BO_ 0 BRIDGE_STATS: 48 XXX
 SG_ FRAMES_TOTAL : 7|16@0+ (1,0) [0|65535] "" XXX
 SG_ FRAMES_VALID : 23|16@0+ (1,0) [0|65535] "" XXX
 SG_ CRC_FAIL : 39|16@0+ (1,0) [0|65535] "" XXX
 SG_ JUNK : 55|16@0+ (1,0) [0|65535] "" XXX
 SG_ TAIL_INCOMPLETE : 71|16@0+ (1,0) [0|65535] "" XXX
 SG_ NOTIFY_DROPPED : 87|16@0+ (1,0) [0|65535] "" XXX
 SG_ INJECT_REQUESTS : 103|16@0+ (1,0) [0|65535] "" XXX
 SG_ INJECT_DONE : 119|16@0+ (1,0) [0|65535] "" XXX
 SG_ INJECT_MISSED : 135|16@0+ (1,0) [0|65535] "" XXX
 SG_ INJECT_REJECTED : 151|16@0+ (1,0) [0|65535] "" XXX
 SG_ INJECT_TABLE_FULL : 167|16@0+ (1,0) [0|65535] "" XXX
 SG_ CAN_TX : 183|16@0+ (1,0) [0|65535] "" XXX
 SG_ CAN_RX : 199|16@0+ (1,0) [0|65535] "" XXX
 SG_ CAN_OUT_DROPPED : 215|16@0+ (1,0) [0|65535] "" XXX
 SG_ DUP_DROPPED : 231|16@0+ (1,0) [0|65535] "" XXX
 SG_ RING_OVERRUN : 247|16@0+ (1,0) [0|65535] "" XXX
 SG_ CAN_INIT : 263|16@0+ (1,0) [0|65535] "" XXX

BO_ 368 RADAR_1: 20 XXX
 SG_ CYCLE_COUNT : 5|6@0+ (1,0) [0|63] "" XXX
 SG_ FLAGS : 7|2@0+ (1,0) [0|3] "" XXX
 SG_ LENGTH : 15|8@0+ (1,0) [0|255] "words" XXX
 SG_ INDEX : 23|8@0+ (1,0) [0|255] "" XXX
 SG_ A_0 : 24|8@1- (1,0) [-128|127] "" XXX
 SG_ B_0 : 32|8@1- (1,0) [-128|127] "" XXX
 SG_ A_1 : 40|8@1- (1,0) [-128|127] "" XXX
 SG_ B_1 : 48|8@1- (1,0) [-128|127] "" XXX
 SG_ A_2 : 56|8@1- (1,0) [-128|127] "" XXX
 SG_ B_2 : 64|8@1- (1,0) [-128|127] "" XXX
 SG_ A_3 : 72|8@1- (1,0) [-128|127] "" XXX
 SG_ B_3 : 80|8@1- (1,0) [-128|127] "" XXX
 SG_ A_4 : 88|8@1- (1,0) [-128|127] "" XXX
 SG_ B_4 : 96|8@1- (1,0) [-128|127] "" XXX
 SG_ A_5 : 104|8@1- (1,0) [-128|127] "" XXX
 SG_ B_5 : 112|8@1- (1,0) [-128|127] "" XXX
 SG_ A_6 : 120|8@1- (1,0) [-128|127] "" XXX
 SG_ B_6 : 128|8@1- (1,0) [-128|127] "" XXX
 SG_ COUNTER : 136|8@1+ (1,0) [0|255] "" XXX

BO_ 384 RADAR_2: 20 XXX
 SG_ CYCLE_COUNT : 5|6@0+ (1,0) [0|63] "" XXX
 SG_ FLAGS : 7|2@0+ (1,0) [0|3] "" XXX
 SG_ LENGTH : 15|8@0+ (1,0) [0|255] "words" XXX
 SG_ INDEX : 23|8@0+ (1,0) [0|255] "" XXX
 SG_ A_0 : 24|8@1- (1,0) [-128|127] "" XXX
 SG_ B_0 : 32|8@1- (1,0) [-128|127] "" XXX
 SG_ A_1 : 40|8@1- (1,0) [-128|127] "" XXX
 SG_ B_1 : 48|8@1- (1,0) [-128|127] "" XXX
 SG_ A_2 : 56|8@1- (1,0) [-128|127] "" XXX
 SG_ B_2 : 64|8@1- (1,0) [-128|127] "" XXX
 SG_ A_3 : 72|8@1- (1,0) [-128|127] "" XXX
 SG_ B_3 : 80|8@1- (1,0) [-128|127] "" XXX
 SG_ A_4 : 88|8@1- (1,0) [-128|127] "" XXX
 SG_ B_4 : 96|8@1- (1,0) [-128|127] "" XXX
 SG_ A_5 : 104|8@1- (1,0) [-128|127] "" XXX
 SG_ B_5 : 112|8@1- (1,0) [-128|127] "" XXX
 SG_ A_6 : 120|8@1- (1,0) [-128|127] "" XXX
 SG_ B_6 : 128|8@1- (1,0) [-128|127] "" XXX
 SG_ COUNTER : 136|8@1+ (1,0) [0|255] "" XXX

BO_ 400 WHEEL_ODOMETRY: 20 XXX
 SG_ CYCLE_COUNT : 5|6@0+ (1,0) [0|63] "" XXX
 SG_ DIRECTION : 7|2@0+ (1,0) [0|3] "" XXX
 SG_ LENGTH : 15|8@0+ (1,0) [0|255] "words" XXX
 SG_ CHECKSUM : 23|8@0+ (1,0) [0|255] "" XXX
 SG_ COUNTER : 27|4@0+ (1,0) [0|15] "" XXX
 SG_ WHEEL_1 : 32|16@1+ (1,0) [0|65535] "" XXX
 SG_ WHEEL_2 : 56|16@1+ (1,0) [0|65535] "" XXX
 SG_ WHEEL_3 : 72|16@1+ (1,0) [0|65535] "" XXX
 SG_ WHEEL_4 : 96|16@1+ (1,0) [0|65535] "" XXX
 SG_ COUNTER_SOMETHING : 112|16@1+ (1,0) [0|65535] "" XXX

BO_ 432 BRAKES: 20 XXX
 SG_ CYCLE_COUNT : 5|6@0+ (1,0) [0|63] "" XXX
 SG_ DIRECTION : 7|2@0+ (1,0) [0|3] "" XXX
 SG_ LENGTH : 15|8@0+ (1,0) [0|255] "words" XXX
 SG_ CHECKSUM : 23|8@0+ (1,0) [0|255] "" XXX
 SG_ COUNTER : 27|4@0+ (1,0) [0|15] "" XXX
 SG_ BRAKE_PRESSURE_1 : 32|16@1+ (1,0) [0|65535] "" XXX
 SG_ BRAKE_PRESSURE_2 : 48|16@1+ (1,0) [0|65535] "" XXX
 SG_ BRAKE_PRESSURE_3 : 64|16@1+ (1,0) [0|65535] "" XXX
 SG_ BRAKE_PRESSURE_4 : 80|16@1+ (1,0) [0|65535] "" XXX
 SG_ NEW_SIGNAL_1 : 99|1@0+ (1,0) [0|1] "" XXX
 SG_ NEW_SIGNAL_2 : 103|2@0+ (1,0) [0|3] "" XXX
 SG_ NEW_SIGNAL_5 : 105|2@0+ (1,0) [0|3] "" XXX
 SG_ NEW_SIGNAL_7 : 115|1@0+ (1,0) [0|1] "" XXX
 SG_ NEW_SIGNAL_3 : 119|2@0+ (1,0) [0|3] "" XXX
 SG_ NEW_SIGNAL_8 : 123|1@0+ (1,0) [0|1] "" XXX
 SG_ NEW_SIGNAL_4 : 127|2@0+ (1,0) [0|3] "" XXX
 SG_ NEW_SIGNAL_6 : 135|8@0+ (1,0) [0|255] "" XXX

BO_ 512 NEW_MSG_2000: 20 XXX
 SG_ CYCLE_COUNT : 5|6@0+ (1,0) [0|63] "" XXX
 SG_ DIRECTION : 7|2@0+ (1,0) [0|3] "" XXX
 SG_ LENGTH : 15|8@0+ (1,0) [0|255] "words" XXX
 SG_ NEW_SIGNAL_1 : 28|12@1+ (1,0) [0|8191] "" XXX
 SG_ NEW_SIGNAL_2 : 40|12@1+ (1,0) [0|4095] "" XXX
 SG_ NEW_SIGNAL_3 : 52|12@1+ (1,0) [0|8191] "" XXX

BO_ 608 NEW_MSG_2600: 20 XXX
 SG_ CYCLE_COUNT : 5|6@0+ (1,0) [0|63] "" XXX
 SG_ DIRECTION : 7|2@0+ (1,0) [0|3] "" XXX
 SG_ LENGTH : 15|8@0+ (1,0) [0|255] "words" XXX
 SG_ NEW_SIGNAL_1 : 40|16@1+ (1,0) [0|2047] "" XXX

BO_ 624 STEERING_WHEEL_7: 20 XXX
 SG_ MULTIPLEXOR M : 16|1@0+ (1,0) [0|1] "" XXX
 SG_ NEW_SIGNAL_1 m0 : 111|8@0+ (1,0) [0|255] "" XXX
 SG_ NEW_SIGNAL_2 m0 : 119|8@0+ (1,0) [0|255] "" XXX
 SG_ CYCLE_COUNT : 5|6@0+ (1,0) [0|63] "" XXX
 SG_ DIRECTION : 7|2@0+ (1,0) [0|3] "" XXX
 SG_ LENGTH : 15|8@0+ (1,0) [0|255] "words" XXX

BO_ 625 STEERING_WHEEL_4: 20 XXX
 SG_ CYCLE_COUNT : 5|6@0+ (1,0) [0|63] "" XXX
 SG_ DIRECTION : 7|2@0+ (1,0) [0|3] "" XXX
 SG_ LENGTH : 15|8@0+ (1,0) [0|255] "words" XXX
 SG_ CHECKSUM : 23|8@0+ (1,0) [0|255] "" XXX
 SG_ COUNTER : 27|4@0+ (1,0) [0|15] "" XXX
 SG_ STEERING_ANGLE : 32|16@1+ (0.04395,-1440.1536) [0|3] "" XXX
 SG_ COUNTER_SOMETHING : 80|12@1+ (1,0) [0|4095] "" XXX

BO_ 641 GEARBOX_1: 20 XXX
 SG_ CYCLE_COUNT : 5|6@0+ (1,0) [0|63] "" XXX
 SG_ DIRECTION : 7|2@0+ (1,0) [0|3] "" XXX
 SG_ LENGTH : 15|8@0+ (1,0) [0|255] "words" XXX
 SG_ CHECKSUM : 23|8@0+ (1,0) [0|255] "" XXX
 SG_ COUNTER : 27|4@0+ (1,0) [0|15] "" XXX
 SG_ RPM : 58|14@1+ (1,0) [0|65535] "" XXX
 SG_ COUNTER_SOMETHING : 80|12@1+ (1,0) [0|65535] "" XXX
 SG_ TORQUE_REQUEST_MAYBE : 112|12@1+ (1,0) [0|65535] "" XXX

BO_ 643 GEARBOX_2: 20 XXX
 SG_ CYCLE_COUNT : 5|6@0+ (1,0) [0|63] "" XXX
 SG_ DIRECTION : 7|2@0+ (1,0) [0|3] "" XXX
 SG_ LENGTH : 15|8@0+ (1,0) [0|255] "words" XXX
 SG_ CHECKSUM : 23|8@0+ (1,0) [0|255] "" XXX
 SG_ COUNTER : 27|4@0+ (1,0) [0|15] "" XXX
 SG_ GEAR : 35|4@0+ (1,0) [0|7] "" XXX
 SG_ OUTPUT_SPEED : 40|16@1+ (1,-2000) [0|255] "" XXX
 SG_ PARK_LOCKED : 57|1@0+ (1,0) [0|1] "" XXX

BO_ 657 NEW_MSG_2901: 20 XXX
 SG_ CYCLE_COUNT : 5|6@0+ (1,0) [0|63] "" XXX
 SG_ DIRECTION : 7|2@0+ (1,0) [0|3] "" XXX
 SG_ LENGTH : 15|8@0+ (1,0) [0|255] "words" XXX
 SG_ CHECKSUM : 23|8@0+ (1,0) [0|255] "" XXX
 SG_ COUNTER : 27|4@0+ (1,0) [0|15] "" XXX
 SG_ NEW_SIGNAL_4 : 32|16@1+ (1,-32768) [0|65535] "" XXX
 SG_ NEW_SIGNAL_3 : 48|16@1+ (1,-32768) [0|65535] "" XXX
 SG_ NEW_SIGNAL_1 : 104|16@1+ (1,-32768) [0|65535] "" XXX
 SG_ NEW_SIGNAL_2 : 128|16@1+ (1,-32768) [0|65535] "" XXX

BO_ 672 NEW_MSG_2A00: 20 XXX
 SG_ CYCLE_COUNT : 5|6@0+ (1,0) [0|63] "" XXX
 SG_ DIRECTION : 7|2@0+ (1,0) [0|3] "" XXX
 SG_ LENGTH : 15|8@0+ (1,0) [0|255] "words" XXX

BO_ 689 BRAKE_PEDAL_1: 20 XXX
 SG_ CYCLE_COUNT : 5|6@0+ (1,0) [0|63] "" XXX
 SG_ DIRECTION : 7|2@0+ (1,0) [0|3] "" XXX
 SG_ LENGTH : 15|8@0+ (1,0) [0|255] "words" XXX
 SG_ CHECKSUM : 23|8@0+ (1,0) [0|255] "" XXX
 SG_ COUNTER : 27|4@0+ (1,0) [0|15] "" XXX
 SG_ BRAKE_RELEASED_1 : 44|1@0+ (1,0) [0|1] "" XXX
 SG_ BRAKE_RELEASED_2 : 46|1@0+ (1,0) [0|1] "" XXX
 SG_ BRAKE_RELEASED_3 : 47|1@0+ (1,0) [0|1] "" XXX
 SG_ EPB_ENGAGE_SOMETHING : 49|2@0+ (1,0) [0|3] "" XXX
 SG_ EPB_RELEASE_SOMETHING : 51|2@0+ (1,0) [0|3] "" XXX
 SG_ NEW_SIGNAL_1 : 53|2@0+ (1,0) [0|3] "" XXX
 SG_ BRAKE_PRESSURE_SOMETHING : 87|8@0+ (1,0) [0|255] "" XXX
 SG_ BRAKE_PEDAL_POSITION_INV : 96|16@1+ (1,0) [0|65535] "" XXX
 SG_ BRAKE_PEDAL_POSITION_1 : 112|12@1+ (1,0) [0|4095] "" XXX
 SG_ BRAKE_PEDAL_POSITION_2 : 124|12@1+ (1,0) [0|15] "" XXX

BO_ 691 BRAKE_PEDAL_2: 20 XXX
 SG_ CYCLE_COUNT : 5|6@0+ (1,0) [0|63] "" XXX
 SG_ DIRECTION : 7|2@0+ (1,0) [0|3] "" XXX
 SG_ LENGTH : 15|8@0+ (1,0) [0|255] "words" XXX
 SG_ CHECKSUM : 23|8@0+ (1,0) [0|255] "" XXX
 SG_ COUNTER : 27|4@0+ (1,0) [0|15] "" XXX
 SG_ BRAKE_PEDAL_POSITION_INV_1 : 32|16@1+ (1,0) [0|65535] "" XXX
 SG_ BRAKE_PEDAL_POSITION_INV_2 : 56|16@1+ (1,0) [0|65535] "" XXX
 SG_ BRAKE_PEDAL_POSITION_3 : 79|8@0+ (1,0) [0|255] "" XXX

BO_ 736 WHEEL_SPEEDS: 20 XXX
 SG_ CYCLE_COUNT : 5|6@0+ (1,0) [0|63] "" XXX
 SG_ DIRECTION : 7|2@0+ (1,0) [0|3] "" XXX
 SG_ LENGTH : 15|8@0+ (1,0) [0|255] "words" XXX
 SG_ CHECKSUM : 23|8@0+ (1,0) [0|255] "" XXX
 SG_ COUNTER : 27|4@0+ (1,0) [0|15] "" XXX
 SG_ RL : 32|16@1+ (0.0198863636363636,-652) [0|65535] "km/h" XXX
 SG_ RR : 48|16@1+ (0.0198863636363636,-652) [0|65535] "km/h" XXX
 SG_ FL : 64|16@1+ (0.0198863636363636,-652) [0|65535] "km/h" XXX
 SG_ FR : 80|16@1+ (0.0198863636363636,-652) [0|65535] "km/h" XXX
 SG_ RR_STATE : 99|4@0+ (1,0) [0|15] "" XXX
 SG_ FL_STATE : 103|4@0+ (1,0) [0|15] "" XXX
 SG_ FR_STATE : 107|4@0+ (1,0) [0|15] "" XXX
 SG_ RL_STATE : 111|4@0+ (1,0) [0|15] "" XXX

BO_ 753 BRAKE_PEDAL_3: 20 XXX
 SG_ CYCLE_COUNT : 5|6@0+ (1,0) [0|63] "" XXX
 SG_ DIRECTION : 7|2@0+ (1,0) [0|3] "" XXX
 SG_ LENGTH : 15|8@0+ (1,0) [0|255] "words" XXX
 SG_ CHECKSUM : 23|8@0+ (1,0) [0|255] "" XXX
 SG_ COUNTER : 27|4@0+ (1,0) [0|15] "" XXX
 SG_ BRAKE_PRESSED_3 : 74|3@0+ (1,0) [0|7] "" XXX
 SG_ NEW_SIGNAL_1 : 75|1@0+ (1,0) [0|1] "" XXX
 SG_ STANDSTILL_SOMETHING : 76|1@0+ (1,0) [0|1] "" XXX
 SG_ NEW_SIGNAL_2 : 79|1@0+ (1,0) [0|1] "" XXX
 SG_ COUNTER_2 : 91|4@0+ (1,0) [0|15] "" XXX
 SG_ BRAKE_PRESSED_2 : 120|1@0+ (1,0) [0|1] "" XXX
 SG_ BRAKE_PRESSED_1 : 122|1@0+ (1,0) [0|1] "" XXX
 SG_ BRAKE_PRESSED_4 : 141|1@0+ (1,0) [0|1] "" XXX

BO_ 784 STEERING_WHEEL_5: 20 XXX
 SG_ CYCLE_COUNT : 5|6@0+ (1,0) [0|63] "" XXX
 SG_ DIRECTION : 7|2@0+ (1,0) [0|3] "" XXX
 SG_ LENGTH : 15|8@0+ (1,0) [0|255] "words" XXX
 SG_ CHECKSUM : 23|8@0+ (1,0) [0|255] "" XXX
 SG_ COUNTER : 27|4@0+ (1,0) [0|15] "" XXX
 SG_ STEERING_TORQUE_1 : 32|12@1+ (0.005,-10) [0|255] "Nm" XXX
 SG_ NEW_SIGNAL_2 : 80|12@1+ (1,0) [0|65535] "" XXX
 SG_ STEERING_TORQUE_2 : 96|12@1+ (0.005,-10) [0|4095] "Nm" XXX
 SG_ NEW_SIGNAL_1 : 115|4@0+ (1,0) [0|15] "" XXX

BO_ 785 STEERING_WHEEL_6: 20 XXX
 SG_ CYCLE_COUNT : 5|6@0+ (1,0) [0|63] "" XXX
 SG_ DIRECTION : 7|2@0+ (1,0) [0|3] "" XXX
 SG_ LENGTH : 15|8@0+ (1,0) [0|255] "words" XXX
 SG_ CHECKSUM : 23|8@0+ (1,0) [0|255] "" XXX
 SG_ COUNTER : 27|4@0+ (1,0) [0|15] "" XXX
 SG_ STEERING_RATE_SOMETHING : 71|8@0+ (1,0) [0|255] "" XXX

BO_ 816 STEERING_WHEEL_3: 20 XXX
 SG_ CYCLE_COUNT : 5|6@0+ (1,0) [0|63] "" XXX
 SG_ DIRECTION : 7|2@0+ (1,0) [0|3] "" XXX
 SG_ LENGTH : 15|8@0+ (1,0) [0|255] "words" XXX
 SG_ CHECKSUM : 23|8@0+ (1,0) [0|255] "" XXX
 SG_ COUNTER : 27|4@0+ (1,0) [0|15] "" XXX
 SG_ STEERING_ANGLE : 32|16@1+ (0.04395,-1440.1536) [0|65535] "" XXX
 SG_ NEW_SIGNAL_2 : 55|8@0+ (1,0) [0|255] "" XXX
 SG_ NEW_SIGNAL_1 : 63|8@0+ (1,0) [0|255] "" XXX
 SG_ NEW_SIGNAL_3 : 77|2@0+ (1,0) [0|3] "" XXX
 SG_ STEERING_TORQUE_EPS : 96|12@1+ (1,-1000) [0|4095] "" XXX

BO_ 880 SPEED: 20 XXX
 SG_ CYCLE_COUNT : 5|6@0+ (1,0) [0|63] "" XXX
 SG_ DIRECTION : 7|2@0+ (1,0) [0|3] "" XXX
 SG_ LENGTH : 15|8@0+ (1,0) [0|255] "words" XXX
 SG_ VEHICLE_SPEED : 32|16@1+ (0.015625,0) [0|65535] "" XXX
 SG_ DRIVING_STATUS : 52|2@1+ (1,0) [0|7] "" XXX

BO_ 897 KINEMATICS_1: 20 XXX
 SG_ CYCLE_COUNT : 5|6@0+ (1,0) [0|63] "" XXX
 SG_ DIRECTION : 7|2@0+ (1,0) [0|3] "" XXX
 SG_ LENGTH : 15|8@0+ (1,0) [0|255] "words" XXX
 SG_ CHECKSUM : 23|8@0+ (1,0) [0|255] "" XXX
 SG_ COUNTER : 27|4@0+ (1,0) [0|15] "" XXX
 SG_ PITCH : 32|12@1+ (1,0) [0|65535] "" XXX
 SG_ ROLL : 48|12@1+ (1,0) [0|65535] "" XXX
 SG_ Z_RATE_MAYBE : 64|12@1+ (1,0) [0|65535] "" XXX
 SG_ COUNTER_SOMETHING : 80|12@1+ (1,0) [0|65535] "" XXX
 SG_ YAW_RATE : 96|16@1+ (1,-32768) [0|65535] "" XXX

BO_ 898 KINEMATICS_2: 20 XXX
 SG_ CYCLE_COUNT : 5|6@0+ (1,0) [0|63] "" XXX
 SG_ DIRECTION : 7|2@0+ (1,0) [0|3] "" XXX
 SG_ LENGTH : 15|8@0+ (1,0) [0|255] "words" XXX
 SG_ CHECKSUM : 87|8@0+ (1,0) [0|255] "" XXX
 SG_ COUNTER : 91|4@0+ (1,0) [0|15] "" XXX
 SG_ YAW_RATE : 96|16@1+ (1,-32768) [0|65535] "" XXX

BO_ 913 KINEMATICS_3: 20 XXX
 SG_ CYCLE_COUNT : 5|6@0+ (1,0) [0|63] "" XXX
 SG_ DIRECTION : 7|2@0+ (1,0) [0|3] "" XXX
 SG_ LENGTH : 15|8@0+ (1,0) [0|255] "words" XXX
 SG_ CHECKSUM : 23|8@0+ (1,0) [0|255] "" XXX
 SG_ COUNTER : 27|4@0+ (1,0) [0|15] "" XXX
 SG_ YAW_RATE : 32|16@1+ (1,-32768) [0|65535] "" XXX

BO_ 914 KINEMATICS_4: 20 XXX
 SG_ CYCLE_COUNT : 5|6@0+ (1,0) [0|63] "" XXX
 SG_ DIRECTION : 7|2@0+ (1,0) [0|3] "" XXX
 SG_ LENGTH : 15|8@0+ (1,0) [0|255] "words" XXX
 SG_ CHECKSUM : 23|8@0+ (1,0) [0|255] "" XXX
 SG_ COUNTER : 27|4@0+ (1,0) [0|15] "" XXX
 SG_ ACCELERATION : 32|16@1+ (0.0025,-81.25) [0|65535] "" XXX
 SG_ SPEED : 48|16@1+ (1,0) [0|65535] "" XXX

BO_ 915 KINEMATICS_5: 20 XXX
 SG_ CYCLE_COUNT : 5|6@0+ (1,0) [0|63] "" XXX
 SG_ DIRECTION : 7|2@0+ (1,0) [0|3] "" XXX
 SG_ LENGTH : 15|8@0+ (1,0) [0|255] "words" XXX
 SG_ CHECKSUM : 23|8@0+ (1,0) [0|255] "" XXX
 SG_ COUNTER : 27|4@0+ (1,0) [0|15] "" XXX
 SG_ YAW_RATE : 32|16@1+ (1,-32768) [0|65535] "" XXX

BO_ 929 NEW_MSG_3A01: 20 XXX
 SG_ VALID M : 30|1@0+ (1,0) [0|1] "" XXX
 SG_ COUNTER m1 : 27|4@0+ (1,0) [0|15] "" XXX
 SG_ CYCLE_COUNT : 5|6@0+ (1,0) [0|63] "" XXX
 SG_ DIRECTION : 7|2@0+ (1,0) [0|3] "" XXX
 SG_ LENGTH : 15|8@0+ (1,0) [0|255] "words" XXX
 SG_ CHECKSUM : 23|8@0+ (1,0) [0|255] "" XXX

BO_ 930 NEW_MSG_3A02: 20 XXX
 SG_ CYCLE_COUNT : 5|6@0+ (1,0) [0|63] "" XXX
 SG_ DIRECTION : 7|2@0+ (1,0) [0|3] "" XXX
 SG_ LENGTH : 15|8@0+ (1,0) [0|255] "words" XXX
 SG_ CHECKSUM : 23|8@0+ (1,0) [0|255] "" XXX
 SG_ COUNTER : 27|4@0+ (1,0) [0|15] "" XXX

BO_ 931 CRUISE_STATE: 20 XXX
 SG_ CYCLE_COUNT : 5|6@0+ (1,0) [0|63] "" XXX
 SG_ DIRECTION : 7|2@0+ (1,0) [0|3] "" XXX
 SG_ LENGTH : 15|8@0+ (1,0) [0|255] "words" XXX
 SG_ CHECKSUM : 23|8@0+ (1,0) [0|255] "" XXX
 SG_ COUNTER : 27|4@0+ (1,0) [0|15] "" XXX
 SG_ SET_ME_0x2 : 31|4@0+ (1,0) [0|15] "" XXX
 SG_ SET_ME_0xFA : 47|8@0+ (1,0) [0|255] "" XXX
 SG_ ACCELERATION_REQUEST : 48|16@1+ (0.0015,-48) [-48|50.3] "m/s2" XXX
 SG_ CRUISE_ENGAGED_1 : 67|1@0+ (1,0) [0|1] "" XXX
 SG_ CRUISE_ENGAGED_2 : 69|1@0+ (1,0) [0|1] "" XXX
 SG_ SET_ME_0x1 : 73|1@0+ (1,0) [0|1] "" XXX
 SG_ CRUISE_ENGAGED_3 : 75|2@0+ (1,0) [0|3] "" XXX
 SG_ SET_ME_0xFFFF : 80|16@1+ (1,0) [0|65535] "" XXX
 SG_ NEW_SIGNAL_2 : 96|11@1+ (1,0) [0|2047] "" XXX
 SG_ SET_ME_0xF : 107|5@1+ (1,0) [0|31] "" XXX
 SG_ SET_ME_0xFFFFFFFF : 112|32@1+ (1,0) [0|4294967295] "" XXX

BO_ 944 STEERING_WHEEL_1: 20 XXX
 SG_ CYCLE_COUNT : 5|6@0+ (1,0) [0|63] "" XXX
 SG_ DIRECTION : 7|2@0+ (1,0) [0|3] "" XXX
 SG_ LENGTH : 15|8@0+ (1,0) [0|255] "words" XXX
 SG_ CHECKSUM : 23|8@0+ (1,0) [0|255] "" XXX
 SG_ COUNTER : 27|4@0+ (1,0) [0|15] "" XXX
 SG_ STEERING_ANGLE : 32|16@1+ (0.04395,-1440.1536) [0|65535] "" XXX

BO_ 945 STEERING_WHEEL_2: 20 XXX
 SG_ CYCLE_COUNT : 5|6@0+ (1,0) [0|63] "" XXX
 SG_ DIRECTION : 7|2@0+ (1,0) [0|3] "" XXX
 SG_ LENGTH : 15|8@0+ (1,0) [0|255] "words" XXX
 SG_ STEERING_ANGLE_1 : 24|16@1+ (0.04395,-1098.75) [0|65535] "" XXX
 SG_ STEER_TORQUE_SOMETHING : 40|12@1+ (1,-2046) [0|65535] "" XXX
 SG_ NEW_SIGNAL_2 : 62|1@0+ (1,0) [0|1] "" XXX
 SG_ HANDS_OFF_WHEEL : 63|1@0+ (1,0) [0|1] "" XXX
 SG_ STEERING_ANGLE_2 : 96|16@1+ (0.04395,-1098.75) [0|65535] "" XXX
 SG_ NEW_SIGNAL_1 : 113|2@0+ (1,0) [0|3] "" XXX

BO_ 1088 EPS_CONTROL: 20 XXX
 SG_ CYCLE_COUNT : 5|6@0+ (1,0) [0|63] "" XXX
 SG_ DIRECTION : 7|2@0+ (1,0) [0|3] "" XXX
 SG_ LENGTH : 15|8@0+ (1,0) [0|255] "words" XXX
 SG_ CHECKSUM_1 : 23|8@0+ (1,0) [0|255] "" XXX
 SG_ COUNTER_1 : 27|4@0+ (1,0) [0|15] "" XXX
 SG_ SET_ME_0xF_1 : 31|4@0+ (1,0) [0|15] "" XXX
 SG_ SET_ME_0xD0 : 39|8@0+ (1,0) [0|255] "" XXX
 SG_ SET_ME_0xE7 : 47|8@0+ (1,0) [0|255] "" XXX
 SG_ NEW_SIGNAL_2 : 55|8@0+ (1,0) [0|255] "" XXX
 SG_ NEW_SIGNAL_1 : 56|8@1+ (1,0) [0|255] "" XXX
 SG_ NEW_SIGNAL_7 : 67|4@0+ (1,0) [0|7] "" XXX
 SG_ TORQUE_MODE : 75|4@0+ (1,0) [0|15] "" XXX
 SG_ TORQUE_REQUEST_1 : 76|1@0+ (1,0) [0|1] "" XXX
 SG_ CHECKSUM_2 : 87|8@0+ (1,0) [0|255] "" XXX
 SG_ COUNTER_2 : 91|4@0+ (1,0) [0|15] "" XXX
 SG_ SET_ME_0xF_2 : 95|4@0+ (1,0) [0|15] "" XXX
 SG_ TORQUE : 96|12@1+ (0.005,-10) [0|4095] "Nm" XXX
 SG_ TORQUE_MODE_CPY : 111|4@0+ (1,0) [0|15] "" XXX
 SG_ SET_ME_0xFF_1 : 119|8@0+ (1,0) [0|255] "" XXX
 SG_ SET_ME_0xFF_2 : 127|8@0+ (1,0) [0|255] "" XXX
 SG_ SET_ME_0xF_3 : 131|4@0+ (1,0) [0|15] "" XXX
 SG_ TORQUE_REQUEST_2 : 133|2@0+ (1,0) [0|3] "" XXX
 SG_ LKA_STATE : 139|4@0+ (1,0) [0|255] "" XXX
 SG_ TORQUE_REQUEST_3 : 140|1@0+ (1,0) [0|1] "" XXX

BO_ 1089 NEW_MSG_4401: 20 XXX
 SG_ CYCLE_COUNT : 5|6@0+ (1,0) [0|63] "" XXX
 SG_ DIRECTION : 7|2@0+ (1,0) [0|3] "" XXX
 SG_ LENGTH : 15|8@0+ (1,0) [0|255] "words" XXX
 SG_ NEW_SIGNAL_1 : 71|4@0+ (1,0) [0|15] "" XXX
 SG_ NEW_SIGNAL_2 : 79|8@0+ (1,0) [0|255] "" XXX

BO_ 1090 NEW_MSG_4402: 20 XXX
 SG_ CYCLE_COUNT : 5|6@0+ (1,0) [0|63] "" XXX
 SG_ DIRECTION : 7|2@0+ (1,0) [0|3] "" XXX
 SG_ LENGTH : 15|8@0+ (1,0) [0|255] "words" XXX
 SG_ NEW_SIGNAL_1 : 143|8@0+ (1,0) [0|255] "" XXX

BO_ 1104 STEERING_WHEEL_8: 20 XXX
 SG_ CYCLE_COUNT : 5|6@0+ (1,0) [0|63] "" XXX
 SG_ DIRECTION : 7|2@0+ (1,0) [0|3] "" XXX
 SG_ LENGTH : 15|8@0+ (1,0) [0|255] "words" XXX
 SG_ CHECKSUM : 23|8@0+ (1,0) [0|255] "" XXX
 SG_ COUNTER : 27|4@0+ (1,0) [0|15] "" XXX
 SG_ STEERING_ANGLE_1 : 32|16@1+ (1,-32768) [0|65535] "" XXX
 SG_ STEERING_ANGLE_2 : 64|16@1+ (1,-32768) [0|65535] "" XXX
 SG_ STEERING_ANGLE_3 : 80|16@1+ (1,-32768) [0|511] "" XXX

BO_ 1123 NEW_MSG_4603: 20 XXX
 SG_ CYCLE_COUNT : 5|6@0+ (1,0) [0|63] "" XXX
 SG_ DIRECTION : 7|2@0+ (1,0) [0|3] "" XXX
 SG_ LENGTH : 15|8@0+ (1,0) [0|255] "words" XXX
 SG_ CHECKSUM : 23|8@0+ (1,0) [0|255] "" XXX
 SG_ COUNTER : 27|4@0+ (1,0) [0|15] "" XXX
 SG_ CRUISE_STATE_RELATED : 39|8@0+ (1,0) [0|255] "" XXX

BO_ 1152 CRUISE_STATE_2: 20 SAS
 SG_ CYCLE_COUNT : 5|6@0+ (1,0) [0|63] "" XXX
 SG_ DIRECTION : 7|2@0+ (1,0) [0|3] "" XXX
 SG_ LENGTH : 15|8@0+ (1,0) [0|255] "words" XXX
 SG_ CHECKSUM_1 : 23|8@0+ (1,0) [0|255] "" XXX
 SG_ COUNTER_1 : 27|4@0+ (1,0) [0|15] "" XXX
 SG_ SET_ME_0x6 : 31|4@0+ (1,0) [0|15] "" XXX
 SG_ BRAKE_REQUEST : 32|16@1+ (0.0015,-48) [-48|50.3] "m/s2" XXX
 SG_ ACC_ENGAGED : 51|4@0+ (1,0) [0|15] "" XXX
 SG_ BRAKE_MODE : 53|2@0+ (1,0) [0|3] "" XXX
 SG_ SET_ME_0xD8 : 63|8@0+ (1,0) [0|255] "" XXX
 SG_ SET_ME_0xF0 : 71|8@0+ (1,0) [0|255] "" XXX
 SG_ SET_ME_0x20 : 79|8@0+ (1,0) [0|255] "" XXX
 SG_ CHECKSUM_2 : 87|8@0+ (1,0) [0|255] "" XXX
 SG_ COUNTER_2 : 91|4@0+ (1,0) [0|15] "" XXX
 SG_ SET_ME_0x1 : 95|4@0+ (1,0) [0|15] "" XXX
 SG_ SET_ME_0xEC : 103|8@0+ (1,0) [0|255] "" XXX
 SG_ SET_ME_0xFFFFFFFF : 119|32@0+ (1,0) [0|4294967295] "" XXX

BO_ 1153 STEER_REQUEST: 20 SAS
 SG_ CYCLE_COUNT : 5|6@0+ (1,0) [0|63] "" XXX
 SG_ DIRECTION : 7|2@0+ (1,0) [0|3] "" XXX
 SG_ LENGTH : 15|8@0+ (1,0) [0|255] "words" XXX
 SG_ CHECKSUM : 23|8@0+ (1,0) [0|255] "" XXX
 SG_ COUNTER : 27|4@0+ (1,0) [0|15] "" XXX
 SG_ SET_ME_0x9 : 31|4@0+ (1,0) [0|15] "" XXX
 SG_ STEER_ANGLE_REQUEST : 32|16@1+ (0.04395,-1098.75) [-1098.75|1781.51325] "deg" XXX
 SG_ STEER_ANGLE_RATE_REQUEST : 48|16@1+ (0.4395,-14400.657) [-14400.657|14401.9755] "deg/s" XXX
 SG_ ASSIST_MODE : 73|2@0+ (1,0) [0|3] "" XXX
 SG_ REVERSING_ASSIST : 78|5@0+ (1,0) [0|31] "" XXX
 SG_ ASSIST_TORQUE : 95|8@0+ (1,0) [0|255] "" XXX
 SG_ SET_ME_0xFE : 103|8@0+ (1,0) [0|255] "" XXX
 SG_ SET_ME_0x17 : 111|8@0+ (1,0) [0|255] "" XXX
 SG_ SET_ME_0xFF : 119|8@0+ (1,0) [0|255] "" XXX
 SG_ SET_ME_0x3 : 120|2@1+ (1,0) [0|3] "" XXX
 SG_ ACTIVE : 124|4@1+ (1,0) [0|15] "" XXX
 SG_ SET_ME_0xA2 : 135|8@0+ (1,0) [0|255] "" XXX
 SG_ SET_ME_0xFA : 143|8@0+ (1,0) [0|255] "" XXX

BO_ 1154 NEW_MSG_4802: 20 XXX
 SG_ CYCLE_COUNT : 5|6@0+ (1,0) [0|63] "" XXX
 SG_ DIRECTION : 7|2@0+ (1,0) [0|3] "" XXX
 SG_ LENGTH : 15|8@0+ (1,0) [0|255] "words" XXX
 SG_ CHECKSUM : 23|8@0+ (1,0) [0|255] "" XXX
 SG_ COUNTER : 27|4@0+ (1,0) [0|15] "" XXX

BO_ 1489 SET_SPEED: 12 SAS
 SG_ CYCLE_COUNT : 5|6@0+ (1,0) [0|63] "" XXX
 SG_ DIRECTION : 7|2@0+ (1,0) [0|3] "" XXX
 SG_ LENGTH : 15|8@0+ (1,0) [0|255] "words" XXX
 SG_ CHECKSUM : 23|8@0+ (1,0) [0|255] "" XXX
 SG_ COUNTER : 27|4@0+ (1,0) [0|15] "" XXX
 SG_ DISTANCE_SETTING : 43|3@0+ (1,0) [0|7] "" XXX
 SG_ SET_SPEED : 55|8@0+ (1,0) [0|255] "km/h" XXX

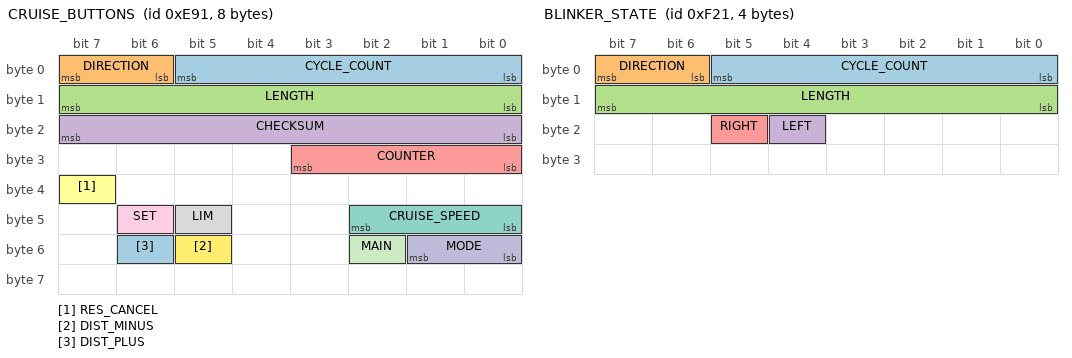
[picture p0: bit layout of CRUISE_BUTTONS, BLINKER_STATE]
BO_ 3729 CRUISE_BUTTONS: 8 XXX
 SG_ CYCLE_COUNT : 5|6@0+ (1,0) [0|63] "" XXX
 SG_ DIRECTION : 7|2@0+ (1,0) [0|3] "" XXX
 SG_ LENGTH : 15|8@0+ (1,0) [0|255] "words" XXX
 SG_ CHECKSUM : 23|8@0+ (1,0) [0|255] "" XXX
 SG_ COUNTER : 27|4@0+ (1,0) [0|15] "" XXX
 SG_ RES_CANCEL : 39|1@0+ (1,0) [0|1] "" XXX
 SG_ CRUISE_SPEED : 42|3@0+ (1,0) [0|7] "" XXX
 SG_ LIM : 45|1@0+ (1,0) [0|1] "" XXX
 SG_ SET : 46|1@0+ (1,0) [0|1] "" XXX
 SG_ MODE : 49|2@0+ (1,0) [0|3] "" XXX
 SG_ MAIN : 50|1@0+ (1,0) [0|1] "" XXX
 SG_ DIST_MINUS : 53|1@0+ (1,0) [0|1] "" XXX
 SG_ DIST_PLUS : 54|1@0+ (1,0) [0|1] "" XXX

BO_ 3873 BLINKER_STATE: 4 XXX
 SG_ CYCLE_COUNT : 5|6@0+ (1,0) [0|63] "" XXX
 SG_ DIRECTION : 7|2@0+ (1,0) [0|3] "" XXX
 SG_ LENGTH : 15|8@0+ (1,0) [0|255] "words" XXX
 SG_ LEFT : 20|1@0+ (1,0) [0|1] "" XXX
 SG_ RIGHT : 21|1@0+ (1,0) [0|1] "" XXX

CM_ BO_ 0 "Bridge diagnostic counters, emitted on CAN id 0 once per FlexRay cycle: 17 big-endian u16 counters (low 16 bits of free-running totals); 7 trailing u16 are zero padding. The per-second rates matter, not the absolute wrapping values.";
CM_ SG_ 0 JUNK "Junk captures: symbols, coldstart attempts, or frames mangled by an in-progress injection";
CM_ SG_ 0 TAIL_INCOMPLETE "Frame sampled before its final byte posted; report deferred a cycle";
CM_ SG_ 0 NOTIFY_DROPPED "Frame-end notifications dropped because the notify ring was full";
CM_ SG_ 0 INJECT_MISSED "Queued injections that missed their cycle or were recovered after stalling";
CM_ SG_ 0 INJECT_REJECTED "Injection requests rejected (bad slot/cycle, no trigger rule, or already armed)";
CM_ SG_ 0 INJECT_TABLE_FULL "Injection requests dropped because the queue was full";
CM_ SG_ 0 CAN_OUT_DROPPED "Reports dropped from the TX queue (CAN link slower than the FlexRay cycle)";
CM_ SG_ 0 DUP_DROPPED "Second-side duplicate captures dropped (each frame is seen on both bus segments)";
CM_ SG_ 0 RING_OVERRUN "Capture DMA ring lapped a chunk before the parser copied it; chunk discarded";
CM_ SG_ 0 CAN_INIT "MCP2518FD CAN controller (re)initialisations";
CM_ SG_ 753 BRAKE_PRESSED_1 "This seems to be the most sensitive brake pressed signal";
CM_ BO_ 929 "NEW_MSG_3A01: companion frame to CRUISE_STATE (multiplexed engaged-status echo: c01300202a03.. engaged vs 001300202603.. disengaged). No accel/brake command; not needed to actuate ACC.";
CM_ BO_ 930 "NEW_MSG_3A02: companion frame; payload varies independently of ACC engagement (counter/status). Not a longitudinal actuator.";
CM_ BO_ 931 "CRUISE_STATE: one of the two ACC longitudinal actuation frames (paired with CRUISE_STATE_2 0x480). Carries ACCELERATION_REQUEST plus engage/standstill state. Observed on bus 0 (src=can).";
CM_ SG_ 931 ACCELERATION_REQUEST "Powertrain (engine/regen) longitudinal accel target. Neutral/0 m/s2 at raw 32000 (empirical zero ~32030); factor 0.0015 m/s2/count fitted vs aEgo in steady cruise/launch (r>0.99). Held at 0 during standstill hold (CRUISE_ENGAGED_3==3). Not the same scaling as KINEMATICS_4.ACCELERATION (0.0025).";
CM_ SG_ 931 CRUISE_ENGAGED_2 "Pre-enable maybe";
CM_ SG_ 931 CRUISE_ENGAGED_3 "Inverse of CRUISE_ENGAGED_1, also 3 at standstill. ==3 while engaged is the standstill-HOLD state: ACCELERATION_REQUEST forced 0, CRUISE_STATE_2.BRAKE_MODE==2 and BRAKE_REQUEST clamped to the hold value (raw ~31196, ~-1.2 m/s2). Goes 3->0 on launch/release.";
CM_ SG_ 931 NEW_SIGNAL_2 "Seems to drop when in turns";
CM_ SG_ 1088 NEW_SIGNAL_2 "0 when active, 0xFE most of the time otherwise";
CM_ SG_ 1088 NEW_SIGNAL_1 "0xFE most of the time";
CM_ SG_ 1088 TORQUE_MODE "2 when active, msotly 14 otherise";
CM_ SG_ 1088 TORQUE_MODE_CPY "mirror of TORQUE_MODE";
CM_ SG_ 1088 LKA_STATE "Ramp from 0-14 on engage/disengage. 5-9 otherwise";
CM_ SG_ 1088 TORQUE_REQUEST_3 "Only 1 while not ramping up/down";
CM_ BO_ 1152 "CRUISE_STATE_2: the other ACC longitudinal actuation frame. Carries BRAKE_REQUEST, BRAKE_MODE and engaged-status bits. Together 0x3a3+0x480 fully drive ACC accel/regen, friction brakes and standstill hold.";
CM_ SG_ 1152 BRAKE_REQUEST "Friction-brake deceleration target. Neutral (no brake) at raw 32000; lower raw = harder braking. Encoded like ACCELERATION_REQUEST (factor 0.0015 m/s2/count, offset -48) so it reads in m/s2; only meaningful when BRAKE_MODE==2. Standstill hold sits at raw ~31196 (~-1.2 m/s2). BRAKE_REQUEST and ACCELERATION_REQUEST do NOT add: in BRAKE_MODE==2 the two are a coordinated split of one decel target across two actuators with a speed-dependent cross-fade (regen/ACCELERATION_REQUEST dominant at speed, friction/BRAKE_REQUEST taking over near stop as ACCELERATION_REQUEST fades to 0). Achieved aEgo tracks ~the deeper of the two (the target), not their sum (sum overpredicts ~2.5-3x). To command decel a in the blend region put a in both signals (they are ~equal at the crossover).";
CM_ SG_ 1152 ACC_ENGAGED "ACC engaged flag (was SET_ME_0x4): 4 while engaged (CRUISE_STATE.CRUISE_ENGAGED_1==1) in any sub-mode, 0 when not engaged.";
CM_ SG_ 1152 BRAKE_MODE "Longitudinal actuator select: 1 = engine/regen only (BRAKE_REQUEST neutral at 32000, ACCELERATION_REQUEST carries the command), 2 = friction brakes engaged (hard decel and standstill hold; BRAKE_REQUEST is live).";
CM_ SG_ 1152 SET_ME_0xD8 "Not constant: 0xD8 while engaged, 0xC0 (bits 0x18 cleared) when disengaged. Carries engaged status alongside ACC_ENGAGED.";
CM_ SG_ 1153 STEER_ANGLE_REQUEST "Steering-wheel angle target. BMW steering resolution = 1/8192 of a full turn per LSB = 360/8192 = 0.0439453 deg (rounded to 0.04395), i.e. 2*pi/8192 = 0.000767 rad. Zero at raw 25000 -> offset = -25000*0.04395 = -1098.75 deg.";
CM_ SG_ 1153 STEER_ANGLE_RATE_REQUEST "Angle-rate feedforward, = d(STEER_ANGLE_REQUEST)/dt. Scaling = 10x the angle LSB: 10*0.04395 = 0.4395 deg/s per LSB (= 10 * 2*pi/8192 rad/s). Zero at raw 32766 -> offset = -32766*0.4395 = -14400.657 deg/s.";
CM_ BO_ 1154 "NEW_MSG_4802: companion to STEER_REQUEST (0x481); carries the steering-family constants (fe17ff13..), not longitudinal ACC.";
CM_ SG_ 1489 SET_SPEED "Signal seems to glitch sometimes";
VAL_ 643 GEAR 2 "N" 4 "D" 5 "R";
VAL_ 1088 TORQUE_REQUEST_2 1 "INACTIVE" 2 "ACTIVE";
VAL_ 1152 ACC_ENGAGED 0 "NOT_ENGAGED" 4 "ENGAGED";
VAL_ 1152 BRAKE_MODE 1 "REGEN_POWERTRAIN" 2 "FRICTION_BRAKE";
VAL_ 1153 ACTIVE 1 "INACTIVE" 2 "ACTIVE";
VAL_ 3729 CRUISE_SPEED 0 "NONE" 1 "UP_1" 2 "UP_10" 5 "DOWN_1" 6 "DOWN_10";
